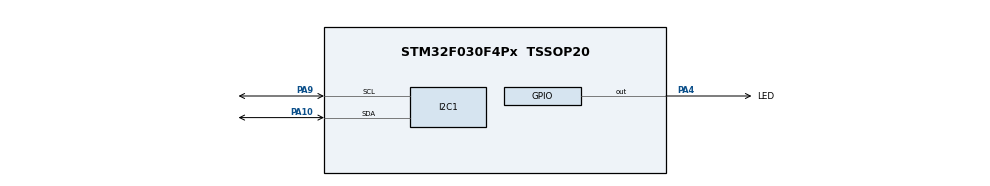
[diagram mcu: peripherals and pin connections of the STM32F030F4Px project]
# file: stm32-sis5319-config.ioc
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Mcu.Family=STM32F0
Mcu.Name=STM32F030F4Px
Mcu.Package=TSSOP20
PA10.Mode=I2C
PA10.Signal=I2C1_SDA
PA4.GPIO_Label=LED
PA4.Signal=GPIO_Output
PA9.Mode=I2C
PA9.Signal=I2C1_SCL
PF0-OSC_IN.Mode=HSE-External-Oscillator
PF0-OSC_IN.Signal=RCC_OSC_IN
PF1-OSC_OUT.Mode=HSE-External-Oscillator
PF1-OSC_OUT.Signal=RCC_OSC_OUT
ProjectManager.HeapSize=0x200
ProjectManager.StackSize=0x400
ProjectManager.TargetToolchain=SW4STM32
RCC.EnbaleCSS=true
RCC.I2c1ClockSelection=RCC_I2C1CLKSOURCE_SYSCLK
RCC.PLLSourceVirtual=RCC_PLLSOURCE_HSE
RCC.SYSCLKSource=RCC_SYSCLKSOURCE_HSE
board=custom

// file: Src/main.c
/* USER CODE BEGIN Header */
/**
  ******************************************************************************
  * @file           : main.c
  * @brief          : Main program body
  ******************************************************************************
  * @attention
  *
  * <h2><center>&copy; Copyright (c) 2021 STMicroelectronics.
  * All rights reserved.</center></h2>
  *
  * This software component is licensed by ST under BSD 3-Clause license,
  * the "License"; You may not use this file except in compliance with the
  * License. You may obtain a copy of the License at:
  *                        opensource.org/licenses/BSD-3-Clause
  *
  ******************************************************************************
  */
/* USER CODE END Header */
#include "main.h"
#include "i2c.h"
#include "gpio.h"

/* USER CODE BEGIN PD */
#define SI5319                             0x68

/* USER CODE END PD */

/* USER CODE BEGIN PV */
//printf("25MHZ->28.8MHZ\n");
const uint8_t data_wr[] = {
        0x00, 0x14,
        0x02, 0x92,
        0x03, 0x15,
        0x05, 0x6d,
        0x06, 0x2a,
        0x08, 0x00,
        0x0a, 0x00,
        0x0b, 0x40,
        0x13, 0x2c,
        0x14, 0x3e,
        0x16, 0xdf,
        0x17, 0x1f,
        0x18, 0x3f,
        0x19, 0x20,
        0x1f, 0x00,
        0x20, 0x00,
        0x21, 0x25,
        0x28, 0x80,
        0x29, 0x02,
        0x2a, 0xab,
        0x2b, 0x00,
        0x2c, 0x00,
        0x2d, 0x18,
        0x2e, 0x00,
        0x2f, 0x00,
        0x30, 0x18,
        0x83, 0x1f,
        0x84, 0x02,
        0x8a, 0x0f,
        0x8b, 0xff,
        0x88, 0x40
};

/* USER CODE END PV */

void SystemClock_Config(void);
/* USER CODE BEGIN PFP */
/**
 * @brief Test code to write esp-i2c-slave
 *        Master device write data to slave(both esp32),
 *        the data will be stored in slave buffer.
 *        We can read them out from slave buffer.
 *
 * ___________________________________________________________________
 * | start | slave_addr + wr_bit + ack | write n bytes + ack  | stop |
 * --------|---------------------------|----------------------|------|
 *
 */
static HAL_StatusTypeDef i2c_master_write_registers(const uint8_t *data_i2c_wr, size_t size) {
    HAL_StatusTypeDef ret;
    for (int i = 0; i < size; i += 2) {
        ret = HAL_I2C_Mem_Write(&hi2c1, SI5319 << 1, data_i2c_wr[i], 1, data_i2c_wr + i + 1, 1, 100);
        if (ret != HAL_OK) {
            return ret;
        }
    }
    return ret;
}

/* USER CODE END PFP */

int main(void) {

    /* MCU Configuration--------------------------------------------------------*/

    /* Reset of all peripherals, Initializes the Flash interface and the Systick. */
    HAL_Init();

    /* Configure the system clock */
    SystemClock_Config();

    /* Initialize all configured peripherals */
    MX_GPIO_Init();
    MX_I2C1_Init();
    /* USER CODE BEGIN 2 */
//    HAL_Delay(300);
    int ret = i2c_master_write_registers(data_wr, sizeof(data_wr) / sizeof(data_wr[0]));

    /* USER CODE END 2 */

    /* Infinite loop */
    while (1) {
        HAL_GPIO_TogglePin(LED_GPIO_Port, LED_Pin);
        if (ret == HAL_OK){
            HAL_Delay(300);
        } else {
            HAL_Delay(100);
        }
    }
}

void SystemClock_Config(void) {
    RCC_OscInitTypeDef RCC_OscInitStruct = {0};
    RCC_ClkInitTypeDef RCC_ClkInitStruct = {0};
    RCC_PeriphCLKInitTypeDef PeriphClkInit = {0};

    /** Initializes the RCC Oscillators according to the specified parameters
    * in the RCC_OscInitTypeDef structure.
    */
    RCC_OscInitStruct.OscillatorType = RCC_OSCILLATORTYPE_HSE;
    RCC_OscInitStruct.HSEState = RCC_HSE_ON;
    RCC_OscInitStruct.PLL.PLLState = RCC_PLL_NONE;
    if (HAL_RCC_OscConfig(&RCC_OscInitStruct) != HAL_OK) {
        Error_Handler();
    }
    /** Initializes the CPU, AHB and APB buses clocks
    */
    RCC_ClkInitStruct.ClockType = RCC_CLOCKTYPE_HCLK | RCC_CLOCKTYPE_SYSCLK
                                  | RCC_CLOCKTYPE_PCLK1;
    RCC_ClkInitStruct.SYSCLKSource = RCC_SYSCLKSOURCE_HSE;
    RCC_ClkInitStruct.AHBCLKDivider = RCC_SYSCLK_DIV1;
    RCC_ClkInitStruct.APB1CLKDivider = RCC_HCLK_DIV1;

    if (HAL_RCC_ClockConfig(&RCC_ClkInitStruct, FLASH_LATENCY_0) != HAL_OK) {
        Error_Handler();
    }
    PeriphClkInit.PeriphClockSelection = RCC_PERIPHCLK_I2C1;
    PeriphClkInit.I2c1ClockSelection = RCC_I2C1CLKSOURCE_SYSCLK;
    if (HAL_RCCEx_PeriphCLKConfig(&PeriphClkInit) != HAL_OK) {
        Error_Handler();
    }
    /** Enables the Clock Security System
    */
    HAL_RCC_EnableCSS();
}

void Error_Handler(void) {
    /* USER CODE BEGIN Error_Handler_Debug */
    /* User can add his own implementation to report the HAL error return state */
    __disable_irq();
    while (1) {
        HAL_GPIO_TogglePin(LED_GPIO_Port, LED_Pin);
        HAL_Delay(30);
    }
    /* USER CODE END Error_Handler_Debug */
}

/************************ (C) COPYRIGHT STMicroelectronics *****END OF FILE****/
